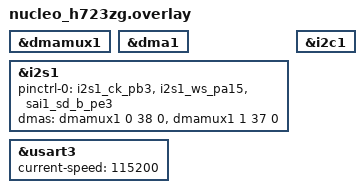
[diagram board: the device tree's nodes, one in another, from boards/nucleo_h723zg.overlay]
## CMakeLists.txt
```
cmake_minimum_required(VERSION 3.20.0)

find_package(Zephyr REQUIRED HINTS $ENV{ZEPHYR_BASE})
project(blinky_custom)

target_sources(app PRIVATE src/main.c)
```

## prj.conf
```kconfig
CONFIG_GPIO=y
CONFIG_STDOUT_CONSOLE=y
# CONFIG_I2S=y

CONFIG_DEBUG=y
CONFIG_ASSERT=y
CONFIG_INIT_STACKS=y
CONFIG_THREAD_STACK_INFO=y


# CONFIG_I2S_STM32=y
CONFIG_MAIN_STACK_SIZE=2048
CONFIG_HEAP_MEM_POOL_SIZE=1024
CONFIG_LOG=y
CONFIG_LOG_DEFAULT_LEVEL=3
CONFIG_SPI=y
CONFIG_SPI_STM32=y
CONFIG_SERIAL=y
CONFIG_UART_CONSOLE=y
CONFIG_CONSOLE=y
CONFIG_PRINTK=y

# CONFIG_UART_CONSOLE_ON_DEV_NAME="USART2"
```

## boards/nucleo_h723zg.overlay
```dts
&dmamux1 {
    status = "okay";
};

&dma1 {
    status = "okay";
};

&i2s1 {
    status = "okay";

    pinctrl-0 = <&i2s1_ck_pb3 &i2s1_ws_pa15 &sai1_sd_b_pe3>;
    pinctrl-names = "default";

    dmas = <&dmamux1 0 38 0>,
           <&dmamux1 1 37 0>;
    dma-names = "tx", "rx";
};

&usart3 {
    status = "okay";
    current-speed = <115200>;
};

&i2c1 {
	status = "okay";
};
```

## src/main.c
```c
#include <zephyr/kernel.h>
#include <zephyr/device.h>
#include <zephyr/drivers/i2s.h>
#include <zephyr/sys/printk.h>
#include <stdint.h>
#include <errno.h>

#define I2S_DEV_NODE      DT_NODELABEL(i2s1)
#define FRAME_CLK_FREQ    16000
#define BLOCK_SIZE        128      /* bytes */
#define NUM_RX_BLOCKS     4        /* number of DMA buffers */
#define TIMEOUT_MS        1000

/* RX buffer pool (DMA-safe, aligned) */
static uint8_t rx_pool[NUM_RX_BLOCKS][BLOCK_SIZE] __aligned(4);

void main(void)
{
    const struct device *i2s = DEVICE_DT_GET(I2S_DEV_NODE);

    if (!device_is_ready(i2s)) {
        printk("I2S device not ready!\n");
        return;
    }

    struct i2s_config cfg = {
        .word_size      = 16,
        .channels       = 1,
        .format         = I2S_FMT_DATA_FORMAT_I2S,
        .options        = I2S_OPT_FRAME_CLK_MASTER | I2S_OPT_BIT_CLK_MASTER,
        .frame_clk_freq = FRAME_CLK_FREQ,
        .block_size     = BLOCK_SIZE,
        .timeout        = TIMEOUT_MS,
    };

    if (i2s_configure(i2s, I2S_DIR_RX, &cfg) != 0) {
        printk("I2S RX configure failed\n");
        return;
    }

    /* Prequeue empty buffers for DMA to fill */
    for (int i = 0; i < NUM_RX_BLOCKS; i++) {
        int r = i2s_buf_write(i2s, rx_pool[i], BLOCK_SIZE);
        if (r < 0) {
            printk("Prequeue %d failed: %d\n", i, r);
            return;
        }
    }

    if (i2s_trigger(i2s, I2S_DIR_RX, I2S_TRIGGER_START) != 0) {
        printk("I2S RX start failed\n");
        return;
    }

    printk("I2S capture started (16 kHz, 16-bit, mono)\n");

    while (1) {
        void *mem_block = NULL;
        size_t size = 0;

        int ret = i2s_read(i2s, &mem_block, &size);
        if (ret < 0) {
            if (ret == -EAGAIN) {
                k_sleep(K_MSEC(1));
                continue;
            }
            printk("i2s_read error: %d\n", ret);
            break;
        }

        if (mem_block && size) {
            /* Process samples */
            int16_t *samples = (int16_t *)mem_block;
            int count = size / sizeof(int16_t);

            /* Print first few samples */
            for (int i = 0; i < MIN(count, 8); i++) {
                printk("%d\n", samples[i]);
            }

            /* Return buffer back to driver */
            int rr = i2s_buf_write(i2s, mem_block, size);
            if (rr < 0) {
                printk("Requeue failed: %d\n", rr);
                break;
            }
        }

        k_sleep(K_MSEC(10));
    }

    (void)i2s_trigger(i2s, I2S_DIR_RX, I2S_TRIGGER_STOP);
}
```

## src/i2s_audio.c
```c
// #include <zephyr.h>
// #include <device.h>
// #include <drivers/i2s.h>
// #include <sys/printk.h>
// #include <stdlib.h>  // for abs()

// #define I2S_DEV DT_LABEL(DT_NODELABEL(i2s1))
// #define BUFFER_SIZE 1024  // bytes (adjust as needed)

// static uint8_t rx_buffer[BUFFER_SIZE];
// static const struct device *i2s_dev;

// void main(void)
// {
//     int ret;
//     struct i2s_config i2s_cfg = {
//         .word_size = 16,                        // 16-bit audio
//         .channels = 1,                          // mono mic
//         .format = I2S_FMT_DATA_FORMAT_I2S,      // try LEFT_JUSTIFIED if needed
//         .options = I2S_OPT_FRAME_CLK_MASTER | I2S_OPT_BIT_CLK_MASTER,
//         .frame_clk_freq = 16000,                // 16 kHz sample rate
//         .block_size = 64,                       // bytes per block
//         .timeout = 1000,                        // ms timeout
//     };

//     printk("Starting I2S MEMS mic capture\n");

//     i2s_dev = device_get_binding(I2S_DEV);
//     if (!i2s_dev) {
//         printk("Failed to get I2S device\n");
//         return;
//     }

//     ret = i2s_configure(i2s_dev, I2S_DIR_RX, &i2s_cfg);
//     if (ret) {
//         printk("Failed to configure I2S: %d\n", ret);
//         return;
//     }

//     ret = i2s_trigger(i2s_dev, I2S_DIR_RX, I2S_TRIGGER_START);
//     if (ret) {
//         printk("Failed to start I2S: %d\n", ret);
//         return;
//     }

//     while (1) {
//         for (int i = 0; i < 100; i++) {
//             printk("%d\n", i);
//             k_sleep(K_MSEC(10));
//         }
//         // struct i2s_buf rx_buf = {
//         //     .buf = rx_buffer,
//         //     .len = sizeof(rx_buffer),
//         // };

//         // ret = i2s_read(i2s_dev, &rx_buf, sizeof(rx_buffer));
//         // if (ret < 0) {
//         //     printk("I2S read error: %d\n", ret);
//         // } else {
//         //     // interpret as 16-bit signed samples
//         //     int16_t *samples = (int16_t *)rx_buffer;
//         //     int sample_count = ret / 2; // 2 bytes per sample

//         //     // Print each sample as plain integer (plotter-friendly)
//         //     for (int i = 0; i < sample_count; i++) {
//         //         printk("%d\n", samples[i]);
//         //         k_sleep(K_MSEC(5));  // pause slightly to avoid overwhelming UART
//         //     }
//         // }

//         // // optional small sleep to throttle loop
//         // k_sleep(K_MSEC(10));
//     }
// }
```
